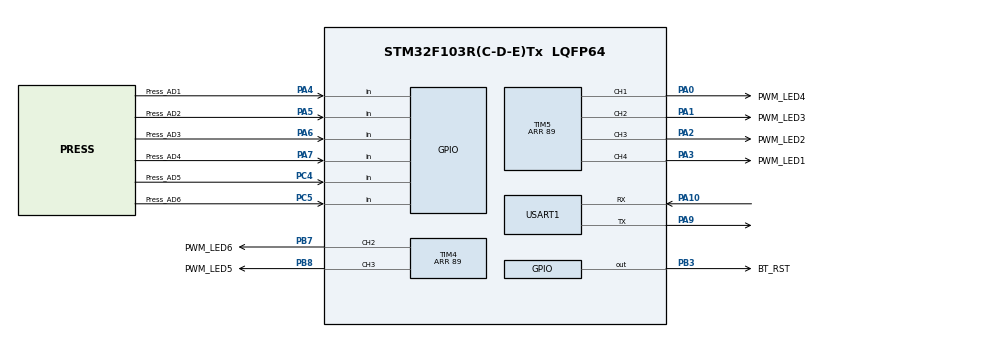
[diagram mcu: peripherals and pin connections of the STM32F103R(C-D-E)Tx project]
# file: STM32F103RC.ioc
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Dma.Request0=TIM5_CH1
Dma.Request1=TIM5_CH2
Dma.Request2=TIM5_CH3/UP
Dma.Request3=TIM5_CH4/TRIG
Dma.Request4=TIM4_CH2
Dma.Request5=TIM4_CH3
Dma.TIM4_CH2.4.Direction=DMA_MEMORY_TO_PERIPH
Dma.TIM4_CH2.4.Instance=DMA1_Channel4
Dma.TIM4_CH2.4.MemDataAlignment=DMA_MDATAALIGN_HALFWORD
Dma.TIM4_CH2.4.MemInc=DMA_MINC_ENABLE
Dma.TIM4_CH2.4.Mode=DMA_NORMAL
Dma.TIM4_CH2.4.PeriphDataAlignment=DMA_PDATAALIGN_HALFWORD
Dma.TIM4_CH2.4.PeriphInc=DMA_PINC_DISABLE
Dma.TIM4_CH2.4.Priority=DMA_PRIORITY_LOW
Dma.TIM4_CH3.5.Direction=DMA_MEMORY_TO_PERIPH
Dma.TIM4_CH3.5.Instance=DMA1_Channel5
Dma.TIM4_CH3.5.MemDataAlignment=DMA_MDATAALIGN_HALFWORD
Dma.TIM4_CH3.5.MemInc=DMA_MINC_ENABLE
Dma.TIM4_CH3.5.Mode=DMA_NORMAL
Dma.TIM4_CH3.5.PeriphDataAlignment=DMA_PDATAALIGN_HALFWORD
Dma.TIM4_CH3.5.PeriphInc=DMA_PINC_DISABLE
Dma.TIM4_CH3.5.Priority=DMA_PRIORITY_LOW
Dma.TIM5_CH1.0.Direction=DMA_MEMORY_TO_PERIPH
Dma.TIM5_CH1.0.Instance=DMA2_Channel5
Dma.TIM5_CH1.0.MemDataAlignment=DMA_MDATAALIGN_HALFWORD
Dma.TIM5_CH1.0.MemInc=DMA_MINC_ENABLE
Dma.TIM5_CH1.0.Mode=DMA_NORMAL
Dma.TIM5_CH1.0.PeriphDataAlignment=DMA_PDATAALIGN_HALFWORD
Dma.TIM5_CH1.0.PeriphInc=DMA_PINC_DISABLE
Dma.TIM5_CH1.0.Priority=DMA_PRIORITY_LOW
Dma.TIM5_CH2.1.Direction=DMA_MEMORY_TO_PERIPH
Dma.TIM5_CH2.1.Instance=DMA2_Channel4
Dma.TIM5_CH2.1.MemDataAlignment=DMA_MDATAALIGN_HALFWORD
Dma.TIM5_CH2.1.MemInc=DMA_MINC_ENABLE
Dma.TIM5_CH2.1.Mode=DMA_NORMAL
Dma.TIM5_CH2.1.PeriphDataAlignment=DMA_PDATAALIGN_HALFWORD
Dma.TIM5_CH2.1.PeriphInc=DMA_PINC_DISABLE
Dma.TIM5_CH2.1.Priority=DMA_PRIORITY_LOW
Dma.TIM5_CH3/UP.2.Direction=DMA_MEMORY_TO_PERIPH
Dma.TIM5_CH3/UP.2.Instance=DMA2_Channel2
Dma.TIM5_CH3/UP.2.MemDataAlignment=DMA_MDATAALIGN_HALFWORD
Dma.TIM5_CH3/UP.2.MemInc=DMA_MINC_ENABLE
Dma.TIM5_CH3/UP.2.Mode=DMA_NORMAL
Dma.TIM5_CH3/UP.2.PeriphDataAlignment=DMA_PDATAALIGN_HALFWORD
Dma.TIM5_CH3/UP.2.PeriphInc=DMA_PINC_DISABLE
Dma.TIM5_CH3/UP.2.Priority=DMA_PRIORITY_LOW
Dma.TIM5_CH4/TRIG.3.Direction=DMA_MEMORY_TO_PERIPH
Dma.TIM5_CH4/TRIG.3.Instance=DMA2_Channel1
Dma.TIM5_CH4/TRIG.3.MemDataAlignment=DMA_MDATAALIGN_HALFWORD
Dma.TIM5_CH4/TRIG.3.MemInc=DMA_MINC_ENABLE
Dma.TIM5_CH4/TRIG.3.Mode=DMA_NORMAL
Dma.TIM5_CH4/TRIG.3.PeriphDataAlignment=DMA_PDATAALIGN_HALFWORD
Dma.TIM5_CH4/TRIG.3.PeriphInc=DMA_PINC_DISABLE
Dma.TIM5_CH4/TRIG.3.Priority=DMA_PRIORITY_LOW
IWDG.Prescaler=IWDG_PRESCALER_256
IWDG.Reload=1000
Mcu.Family=STM32F1
Mcu.Name=STM32F103R(C-D-E)Tx
Mcu.Package=LQFP64
NVIC.DMA1_Channel4_IRQn=true\:0\:0\:false\:false\:true\:false\:true
NVIC.DMA1_Channel5_IRQn=true\:0\:0\:false\:false\:true\:false\:true
NVIC.DMA2_Channel1_IRQn=true\:0\:0\:false\:false\:true\:false\:true
NVIC.DMA2_Channel2_IRQn=true\:0\:0\:false\:false\:true\:false\:true
NVIC.DMA2_Channel4_5_IRQn=true\:0\:0\:false\:false\:true\:false\:true
NVIC.PriorityGroup=NVIC_PRIORITYGROUP_4
NVIC.USART1_IRQn=true\:0\:0\:false\:false\:true\:true\:true
PA0-WKUP.GPIO_Label=PWM_LED4
PA0-WKUP.Signal=S_TIM5_CH1
PA1.GPIO_Label=PWM_LED3
PA1.Signal=S_TIM5_CH2
PA10.Mode=Asynchronous
PA10.Signal=USART1_RX
PA13.Mode=Serial_Wire
PA13.Signal=SYS_JTMS-SWDIO
PA14.Mode=Serial_Wire
PA14.Signal=SYS_JTCK-SWCLK
PA2.GPIO_Label=PWM_LED2
PA2.Signal=S_TIM5_CH3
PA3.GPIO_Label=PWM_LED1
PA3.Signal=S_TIM5_CH4
PA4.GPIO_Label=Press_AD1
PA4.Signal=GPIO_Input
PA5.GPIO_Label=Press_AD2
PA5.Signal=GPIO_Input
PA6.GPIO_Label=Press_AD3
PA6.Signal=GPIO_Input
PA7.GPIO_Label=Press_AD4
PA7.Signal=GPIO_Input
PA9.Mode=Asynchronous
PA9.Signal=USART1_TX
PB3.GPIO_Label=BT_RST
PB3.PinState=GPIO_PIN_SET
PB3.Signal=GPIO_Output
PB7.GPIO_Label=PWM_LED6
PB7.Signal=S_TIM4_CH2
PB8.GPIO_Label=PWM_LED5
PB8.Signal=S_TIM4_CH3
PC4.GPIO_Label=Press_AD5
PC4.Signal=GPIO_Input
PC5.GPIO_Label=Press_AD6
PC5.Signal=GPIO_Input
PD0-OSC_IN.Mode=HSE-External-Oscillator
PD0-OSC_IN.Signal=RCC_OSC_IN
PD1-OSC_OUT.Mode=HSE-External-Oscillator
PD1-OSC_OUT.Signal=RCC_OSC_OUT
ProjectManager.HeapSize=0x200
ProjectManager.StackSize=0x400
ProjectManager.TargetToolchain=MDK-ARM V5.32
RCC.AHBFreq_Value=72000000
RCC.APB1CLKDivider=RCC_HCLK_DIV2
RCC.APB1Freq_Value=36000000
RCC.APB1TimFreq_Value=72000000
RCC.APB2Freq_Value=72000000
RCC.APB2TimFreq_Value=72000000
RCC.HCLKFreq_Value=72000000
RCC.PLLMUL=RCC_PLL_MUL9
RCC.PLLSourceVirtual=RCC_PLLSOURCE_HSE
RCC.SYSCLKFreq_VALUE=72000000
RCC.SYSCLKSource=RCC_SYSCLKSOURCE_PLLCLK
RCC.USBFreq_Value=72000000
SH.S_TIM4_CH2.0=TIM4_CH2,PWM Generation2 CH2
SH.S_TIM4_CH3.0=TIM4_CH3,PWM Generation3 CH3
SH.S_TIM5_CH1.0=TIM5_CH1,PWM Generation1 CH1
SH.S_TIM5_CH2.0=TIM5_CH2,PWM Generation2 CH2
SH.S_TIM5_CH3.0=TIM5_CH3,PWM Generation3 CH3
SH.S_TIM5_CH4.0=TIM5_CH4,PWM Generation4 CH4
TIM4.Channel-PWM\ Generation2\ CH2=TIM_CHANNEL_2
TIM4.Channel-PWM\ Generation3\ CH3=TIM_CHANNEL_3
TIM4.Period=89
TIM5.Channel-PWM\ Generation1\ CH1=TIM_CHANNEL_1
TIM5.Channel-PWM\ Generation2\ CH2=TIM_CHANNEL_2
TIM5.Channel-PWM\ Generation3\ CH3=TIM_CHANNEL_3
TIM5.Channel-PWM\ Generation4\ CH4=TIM_CHANNEL_4
TIM5.Period=89
USART1.VirtualMode=VM_ASYNC
VP_IWDG_VS_IWDG.Mode=IWDG_Activate
VP_TIM4_VS_ClockSourceINT.Mode=Internal
VP_TIM5_VS_ClockSourceINT.Mode=Internal
board=custom

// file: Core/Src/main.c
#include "main.h"
#include <stdbool.h>
#include "dma.h"
#include "iwdg.h"
#include "tim.h"
#include "adc.h"
#include "usart.h"
#include "gpio.h"
#include "sys.h"

#include "globaldata.h"
#include "globalfunc.h"
#include "APP.h"
#include "Bluetooth.h"
#include "Initial.h"
#include <stdio.h>
#include "fft.h"
#include "WS2812.h"
#include "USE_JOB1.h"
#include "job1.h"

#include "multi_button.h"

Button button[6];

#define UART_RB_SIZE  1024

static uint8_t g_uart_rb_buf[UART_RB_SIZE];

volatile uint8_t   n_count;
volatile uint8_t   n_done;
volatile uint16_t  adc_value;
volatile uint16_t  adc_d;
volatile uint32_t  fft_start_count = 0;

volatile unsigned short   g_Combo_Max_value;
volatile unsigned short   g_Combo_count;
volatile uint32_t         g_Combo_num;
volatile uint8_t          prew_ch;
volatile uint8_t          m_combo_mode;
volatile uint8_t          m_combo_buf[2];
bool                      g_Combo_flag;
extern  bool                        g_fft_frame_flag;
volatile uint32_t         spp_count;
extern  unsigned char       KONGJI_Flag;
bool  g_PAUSE_Trill_flg;
uint8_t   send_d[3];
extern  bool                            mak_fft_start;

extern  uint8_t                     led_buf[];
extern  uint16_t                    MAG[];
extern  bool                            flag_fft_first;
extern  double                      m_rand;
extern  unsigned short      g_Data_Max_value;
extern  unsigned char       SPP_Connect_Flag;

extern  void    Set_LED_Mode_pwm( uint8_t  pwm );
extern  void    Set_LED_Mode0( void );
void SystemClock_Config( void );

uint8_t button_read( uint8_t button_id )
{
	switch( button_id )
	{
		case 1:
            return Press_AD1;
		case 2:
            return Press_AD2;
		case 3:
            return Press_AD3;
		case 4:
            return Press_AD4;
		case 5:
            return Press_AD5;
		case 6:
            return Press_AD6;
		default:
            return 0;
    }
}

void btn_cb( void *arg )
{
	Button *btn = (Button *)arg;

	if( btn->event == PRESS_DOWN )
	{
        if (g_App_Mode == 3)
        {
            Send_Boxing_Loc_BDP(btn->button_id);
        }
    }
}

int main( void )
{
	/* USER CODE BEGIN 1 */
	//  Flash_EnableReadProtection();   //insert
	/* USER CODE END 1 */

	/* MCU Configuration--------------------------------------------------------*/

	/* Reset of all peripherals, Initializes the Flash interface and the Systick. */
	HAL_Init();

	/* Configure the system clock */
	SystemClock_Config();

	/* Initialize all configured peripherals */
	MX_GPIO_Init();
	MX_DMA_Init();
	MX_TIM5_Init();
	MX_TIM4_Init();
	Led_All_Off();

	rb_init( &g_uart_rb, g_uart_rb_buf, UART_RB_SIZE );
	MX_USART1_UART_Init();
	//等待下一次接收中断
	HAL_UART_Receive_IT( &huart1, &com1_recv_one_byte, 1 );
	//  MX_IWDG_Init();

	System_App_Init();

	MY_ADC_Init();
	TIM3_Init();

	mak_fft_start = true;
	m_combo_mode =  0;
	g_Combo_num = 0;
	g_Combo_count = 0;
	fft_start_count = 0;
	g_Combo_Max_value = 0;
	g_Combo_flag = false;
	spp_count = 0;
	g_PAUSE_Trill_flg = false;
	if( 0 == g_App_Mode_flag )
	{
		Led_All_Off();
		Led_On();
	}

	for( uint8_t i = 0; i < 6; i++ )
	{
		button_init( &button[i], button_read, 0, i + 1 );
		button_attach( &button[i], PRESS_DOWN, btn_cb );
		button_start( &button[i] );
	}
	HAL_GPIO_WritePin( GPIOA, GPIO_PIN_11, GPIO_PIN_RESET );

	// if( !HAL_GPIO_ReadPin( GPIOC, GPIO_PIN_12 ) )
	// {
	//  g_BT_Connect_Flag = 0;
	//  SPP_Connect_Flag = 0;
	//  g_App_Mode_flag = 0;
	//  if( g_BT_Connect_Flag == 0 )
	//  {
	//      Led_On_Mode1( g_BT_Connect_Flag );
	//      if( g_App_Mode != 0 )
	//      {
	//          g_App_Mode = 1;
	//      }
	//  }
	// }
	// else
	// {
	//  if( fft_start_count > 5 )
	//  {
	//      SPP_Connect_Flag = 1;
	//      if( ( g_App_Mode_flag == 0 ) && ( g_BT_Connect_Flag == 0 )    )
	//      {
	//          Led_All_Off();
	//          g_App_Mode_flag = 1;
	//          g_App_Mode = 6;
	//      }
	//      fft_start_count = 5;
	//  }
	// }
	start_job();
	uint32_t old_tick = HAL_GetTick();
    g_ble_info.bleState = 0x03;
	//  while( 1 )
	//  {
	//      void uart_process_task( void );
	//      uart_process_task();
	//      if( BLE_is_connected() )
	//      {
	//          if( fft_start_count > 5 )
	//          {
	//              SPP_Connect_Flag = 1;
	//              if( ( g_App_Mode_flag == 0 ) && ( g_BT_Connect_Flag == 0 )    )
	//              {
	//                  Led_All_Off();
	//                  g_App_Mode_flag = 1;
	//                  g_App_Mode = 6;
	//              }
	//              fft_start_count = 5;
	//          }
	//      }
	//      if( HAL_GetTick() - old_tick > 3000 )
	//      {
	//          break;
	//      }
	//  }

	//  if( HAL_GetTick() - old_tick > 3000 )
	//  {
	//      g_BT_Connect_Flag = 0;
	//      SPP_Connect_Flag = 0;
	//      g_App_Mode_flag = 0;
	//      if( g_BT_Connect_Flag == 0 )
	//      {
	//          Led_On_Mode1( g_BT_Connect_Flag );
	//          if( g_App_Mode != 0 )
	//          {
	//              g_App_Mode = 1;
	//          }
	//      }
	//  }

	/* Infinite loop */
	while ( 1 )
	{
		// if( ( SPP_Connect_Flag == 1 ) && ( mak_fft_start == true ) )
		//此处表示蓝牙开始播放音乐
		// if( ( g_ble_info.connectState == 0x02 ) && ( mak_fft_start == true ) )
		if( g_ble_info.bleState == 0x02 && BLE_is_playing() && mak_fft_start == true )
		{
			const uint32_t fft_adc_d_max = 20;
			if( 1 == KONGJI_Flag )
			{
				g_App_Mode = 3;
				KONGJI_Flag = 0;
			}
			while ( !n_done );
			fft();
			mag_to_buf();
			n_done = 0;

			adc_d = MAG[1];
			if( adc_d > fft_adc_d_max )
			{
				adc_d -= fft_adc_d_max;
			}
			else
			{
				adc_d = 0;
			}
			adc_d = adc_d << 1;

			if( ( adc_d > fft_adc_d_max ) && ( mak_fft_start == true ) )
			{
				adc_d = fft_adc_d_max;
				if( !flag_fft_first )
				{
					Led_All_Off();
					g_App_Mode  = 7;
					flag_fft_first = true;
					g_2000ms_counter = 200;
					g_Data_Max_value = 0;

					FFT_Handle();

				}
				else if( g_2000ms_counter > 600 )
				{
					g_2000ms_counter = 200;
					g_Data_Max_value ++;

					FFT_Handle();

					g_Combo_Max_value = 0;
					g_Song_End_Count = 0;
				}
				else
				{
					g_Combo_Max_value++;
					g_Combo_count++;
				}
			}
		}
		TaskStart();

		if( data_rx_sta )
		{
			data_rx_sta = 0;
			data_rx_job( );
		}
	}
}

void Flash_EnableReadProtection( void )
{

	FLASH_OBProgramInitTypeDef OBInit;

	__HAL_FLASH_PREFETCH_BUFFER_DISABLE();

	HAL_FLASHEx_OBGetConfig( &OBInit );
	if( OBInit.RDPLevel == OB_RDP_LEVEL_0 )
	{
		OBInit.OptionType = OPTIONBYTE_RDP;
		OBInit.RDPLevel = OB_RDP_LEVEL_1;
		HAL_FLASH_Unlock();
		HAL_FLASH_OB_Unlock();
		HAL_FLASHEx_OBProgram( &OBInit );
		HAL_FLASH_OB_Lock();
		HAL_FLASH_Lock();
	}
	__HAL_FLASH_PREFETCH_BUFFER_ENABLE();

}

void SystemClock_Config( void )
{
	RCC_OscInitTypeDef RCC_OscInitStruct = {0};
	RCC_ClkInitTypeDef RCC_ClkInitStruct = {0};

	/** Initializes the RCC Oscillators according to the specified parameters
	* in the RCC_OscInitTypeDef structure.
	*/
	RCC_OscInitStruct.OscillatorType = RCC_OSCILLATORTYPE_LSI | RCC_OSCILLATORTYPE_HSE;
	RCC_OscInitStruct.HSEState = RCC_HSE_ON;
	RCC_OscInitStruct.HSEPredivValue = RCC_HSE_PREDIV_DIV1;
	RCC_OscInitStruct.HSIState = RCC_HSI_ON;
	RCC_OscInitStruct.LSIState = RCC_LSI_ON;
	RCC_OscInitStruct.PLL.PLLState = RCC_PLL_ON;
	RCC_OscInitStruct.PLL.PLLSource = RCC_PLLSOURCE_HSE;
	RCC_OscInitStruct.PLL.PLLMUL = RCC_PLL_MUL9;
	if ( HAL_RCC_OscConfig( &RCC_OscInitStruct ) != HAL_OK )
	{
		Error_Handler();
	}
	/** Initializes the CPU, AHB and APB buses clocks
	*/
	RCC_ClkInitStruct.ClockType = RCC_CLOCKTYPE_HCLK | RCC_CLOCKTYPE_SYSCLK
	                              | RCC_CLOCKTYPE_PCLK1 | RCC_CLOCKTYPE_PCLK2;
	RCC_ClkInitStruct.SYSCLKSource = RCC_SYSCLKSOURCE_PLLCLK;
	RCC_ClkInitStruct.AHBCLKDivider = RCC_SYSCLK_DIV1;
	RCC_ClkInitStruct.APB1CLKDivider = RCC_HCLK_DIV2;
	RCC_ClkInitStruct.APB2CLKDivider = RCC_HCLK_DIV1;

	if ( HAL_RCC_ClockConfig( &RCC_ClkInitStruct, FLASH_LATENCY_2 ) != HAL_OK )
	{
		Error_Handler();
	}
}

void Error_Handler( void )
{
	__disable_irq();
	while ( 1 )
	{
	}
}
